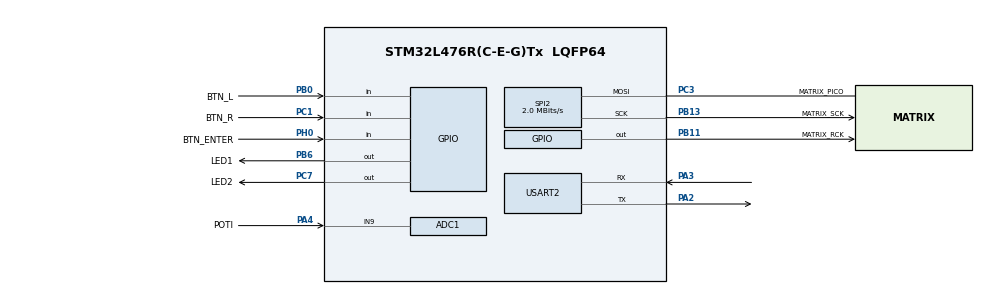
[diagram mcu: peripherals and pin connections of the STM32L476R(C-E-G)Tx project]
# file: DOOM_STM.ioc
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ADC1.Channel-0\#ChannelRegularConversion=ADC_CHANNEL_9
ADC1.ContinuousConvMode=ENABLE
ADC1.NbrOfConversionFlag=1
ADC1.OffsetNumber-0\#ChannelRegularConversion=ADC_OFFSET_NONE
ADC1.Rank-0\#ChannelRegularConversion=1
ADC1.SamplingTime-0\#ChannelRegularConversion=ADC_SAMPLETIME_2CYCLES_5
ADC1.master=1
Mcu.Family=STM32L4
Mcu.Name=STM32L476R(C-E-G)Tx
Mcu.Package=LQFP64
NVIC.PriorityGroup=NVIC_PRIORITYGROUP_4
PA2.Mode=Asynchronous
PA2.Signal=USART2_TX
PA3.Mode=Asynchronous
PA3.Signal=USART2_RX
PA4.GPIO_Label=POTI
PA4.Signal=ADCx_IN9
PB0.GPIO_Label=BTN_L
PB0.Signal=GPIO_Input
PB11.GPIO_Label=MATRIX_RCK
PB11.Signal=GPIO_Output
PB13.GPIO_Label=MATRIX_SCK
PB13.Mode=Simplex_Bidirectional_Master
PB13.Signal=SPI2_SCK
PB6.GPIO_Label=LED1
PB6.Signal=GPIO_Output
PC1.GPIO_Label=BTN_R
PC1.Signal=GPIO_Input
PC3.GPIO_Label=MATRIX_PICO
PC3.Mode=Simplex_Bidirectional_Master
PC3.Signal=SPI2_MOSI
PC7.GPIO_Label=LED2
PC7.Signal=GPIO_Output
PH0-OSC_IN\ (PH0).GPIO_Label=BTN_ENTER
PH0-OSC_IN\ (PH0).Signal=GPIO_Input
ProjectManager.HeapSize=0x200
ProjectManager.StackSize=0x400
ProjectManager.TargetToolchain=STM32CubeIDE
RCC.ADCFreq_Value=32000000
RCC.HSE_VALUE=8000000
RCC.HSI_VALUE=16000000
RCC.LSE_VALUE=32768
RCC.MSI_VALUE=4000000
RCC.PLLSAI1N=16
RCC.USBFreq_Value=32000000
RCC.VCOOutputFreq_Value=32000000
SH.ADCx_IN9.0=ADC1_IN9,IN9-Single-Ended
SPI2.CalculateBaudRate=2.0 MBits/s
SPI2.Direction=SPI_DIRECTION_1LINE
SPI2.Mode=SPI_MODE_MASTER
SPI2.VirtualType=VM_MASTER
USART2.VirtualMode-Asynchronous=VM_ASYNC
board=custom

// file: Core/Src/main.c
/* USER CODE BEGIN Header */
/**
 ******************************************************************************
 * @file           : main.c
 * @brief          : Main program body
 * @author         : Vikram Damani   (honestly so much of this is autogenerated that i dont think i should be credited alone up here)
 ******************************************************************************
 * @attention
 *
 * Copyright (c) 2023 STMicroelectronics.
 * All rights reserved.
 *
 * This software is licensed under terms that can be found in the LICENSE file
 * in the root directory of this software component.
 * If no LICENSE file comes with this software, it is provided AS-IS.
 *
 ******************************************************************************
 */
/* USER CODE END Header */
#include "main.h"

ADC_HandleTypeDef hadc1;

SPI_HandleTypeDef hspi2;

UART_HandleTypeDef huart2;

void SystemClock_Config(void);
static void MX_GPIO_Init(void);
static void MX_USART2_UART_Init(void);
static void MX_ADC1_Init(void);
static void MX_SPI2_Init(void);

int main(void)
{

  /* MCU Configuration--------------------------------------------------------*/

  /* Reset of all peripherals, Initializes the Flash interface and the Systick. */
  HAL_Init();

  /* Configure the system clock */
  SystemClock_Config();

  /* Initialize all configured peripherals */
  MX_GPIO_Init();
  MX_USART2_UART_Init();
  MX_ADC1_Init();
  MX_SPI2_Init();

  /* Infinite loop */
    while (1) {

    }
}

void SystemClock_Config(void)
{
  RCC_OscInitTypeDef RCC_OscInitStruct = {0};
  RCC_ClkInitTypeDef RCC_ClkInitStruct = {0};

  /** Configure the main internal regulator output voltage
  */
  if (HAL_PWREx_ControlVoltageScaling(PWR_REGULATOR_VOLTAGE_SCALE1) != HAL_OK)
  {
    Error_Handler();
  }

  /** Initializes the RCC Oscillators according to the specified parameters
  * in the RCC_OscInitTypeDef structure.
  */
  RCC_OscInitStruct.OscillatorType = RCC_OSCILLATORTYPE_MSI;
  RCC_OscInitStruct.MSIState = RCC_MSI_ON;
  RCC_OscInitStruct.MSICalibrationValue = 0;
  RCC_OscInitStruct.MSIClockRange = RCC_MSIRANGE_6;
  RCC_OscInitStruct.PLL.PLLState = RCC_PLL_NONE;
  if (HAL_RCC_OscConfig(&RCC_OscInitStruct) != HAL_OK)
  {
    Error_Handler();
  }

  /** Initializes the CPU, AHB and APB buses clocks
  */
  RCC_ClkInitStruct.ClockType = RCC_CLOCKTYPE_HCLK|RCC_CLOCKTYPE_SYSCLK
                              |RCC_CLOCKTYPE_PCLK1|RCC_CLOCKTYPE_PCLK2;
  RCC_ClkInitStruct.SYSCLKSource = RCC_SYSCLKSOURCE_MSI;
  RCC_ClkInitStruct.AHBCLKDivider = RCC_SYSCLK_DIV1;
  RCC_ClkInitStruct.APB1CLKDivider = RCC_HCLK_DIV1;
  RCC_ClkInitStruct.APB2CLKDivider = RCC_HCLK_DIV1;

  if (HAL_RCC_ClockConfig(&RCC_ClkInitStruct, FLASH_LATENCY_0) != HAL_OK)
  {
    Error_Handler();
  }
}

static void MX_ADC1_Init(void)
{

  ADC_MultiModeTypeDef multimode = {0};
  ADC_ChannelConfTypeDef sConfig = {0};

  /** Common config
  */
  hadc1.Instance = ADC1;
  hadc1.Init.ClockPrescaler = ADC_CLOCK_ASYNC_DIV1;
  hadc1.Init.Resolution = ADC_RESOLUTION_12B;
  hadc1.Init.DataAlign = ADC_DATAALIGN_RIGHT;
  hadc1.Init.ScanConvMode = ADC_SCAN_DISABLE;
  hadc1.Init.EOCSelection = ADC_EOC_SINGLE_CONV;
  hadc1.Init.LowPowerAutoWait = DISABLE;
  hadc1.Init.ContinuousConvMode = ENABLE;
  hadc1.Init.NbrOfConversion = 1;
  hadc1.Init.DiscontinuousConvMode = DISABLE;
  hadc1.Init.ExternalTrigConv = ADC_SOFTWARE_START;
  hadc1.Init.ExternalTrigConvEdge = ADC_EXTERNALTRIGCONVEDGE_NONE;
  hadc1.Init.DMAContinuousRequests = DISABLE;
  hadc1.Init.Overrun = ADC_OVR_DATA_PRESERVED;
  hadc1.Init.OversamplingMode = DISABLE;
  if (HAL_ADC_Init(&hadc1) != HAL_OK)
  {
    Error_Handler();
  }

  /** Configure the ADC multi-mode
  */
  multimode.Mode = ADC_MODE_INDEPENDENT;
  if (HAL_ADCEx_MultiModeConfigChannel(&hadc1, &multimode) != HAL_OK)
  {
    Error_Handler();
  }

  /** Configure Regular Channel
  */
  sConfig.Channel = ADC_CHANNEL_9;
  sConfig.Rank = ADC_REGULAR_RANK_1;
  sConfig.SamplingTime = ADC_SAMPLETIME_2CYCLES_5;
  sConfig.SingleDiff = ADC_SINGLE_ENDED;
  sConfig.OffsetNumber = ADC_OFFSET_NONE;
  sConfig.Offset = 0;
  if (HAL_ADC_ConfigChannel(&hadc1, &sConfig) != HAL_OK)
  {
    Error_Handler();
  }

}

static void MX_SPI2_Init(void)
{

  /* SPI2 parameter configuration*/
  hspi2.Instance = SPI2;
  hspi2.Init.Mode = SPI_MODE_MASTER;
  hspi2.Init.Direction = SPI_DIRECTION_1LINE;
  hspi2.Init.DataSize = SPI_DATASIZE_4BIT;
  hspi2.Init.CLKPolarity = SPI_POLARITY_LOW;
  hspi2.Init.CLKPhase = SPI_PHASE_1EDGE;
  hspi2.Init.NSS = SPI_NSS_SOFT;
  hspi2.Init.BaudRatePrescaler = SPI_BAUDRATEPRESCALER_2;
  hspi2.Init.FirstBit = SPI_FIRSTBIT_MSB;
  hspi2.Init.TIMode = SPI_TIMODE_DISABLE;
  hspi2.Init.CRCCalculation = SPI_CRCCALCULATION_DISABLE;
  hspi2.Init.CRCPolynomial = 7;
  hspi2.Init.CRCLength = SPI_CRC_LENGTH_DATASIZE;
  hspi2.Init.NSSPMode = SPI_NSS_PULSE_ENABLE;
  if (HAL_SPI_Init(&hspi2) != HAL_OK)
  {
    Error_Handler();
  }

}

static void MX_USART2_UART_Init(void)
{

  huart2.Instance = USART2;
  huart2.Init.BaudRate = 115200;
  huart2.Init.WordLength = UART_WORDLENGTH_8B;
  huart2.Init.StopBits = UART_STOPBITS_1;
  huart2.Init.Parity = UART_PARITY_NONE;
  huart2.Init.Mode = UART_MODE_TX_RX;
  huart2.Init.HwFlowCtl = UART_HWCONTROL_NONE;
  huart2.Init.OverSampling = UART_OVERSAMPLING_16;
  huart2.Init.OneBitSampling = UART_ONE_BIT_SAMPLE_DISABLE;
  huart2.AdvancedInit.AdvFeatureInit = UART_ADVFEATURE_NO_INIT;
  if (HAL_UART_Init(&huart2) != HAL_OK)
  {
    Error_Handler();
  }

}

static void MX_GPIO_Init(void)
{
  GPIO_InitTypeDef GPIO_InitStruct = {0};

  /* GPIO Ports Clock Enable */
  __HAL_RCC_GPIOH_CLK_ENABLE();
  __HAL_RCC_GPIOC_CLK_ENABLE();
  __HAL_RCC_GPIOA_CLK_ENABLE();
  __HAL_RCC_GPIOB_CLK_ENABLE();

  /*Configure GPIO pin Output Level */
  HAL_GPIO_WritePin(GPIOB, MATRIX_RCK_Pin|LED1_Pin, GPIO_PIN_RESET);

  /*Configure GPIO pin Output Level */
  HAL_GPIO_WritePin(LED2_GPIO_Port, LED2_Pin, GPIO_PIN_RESET);

  /*Configure GPIO pin : BTN_ENTER_Pin */
  GPIO_InitStruct.Pin = BTN_ENTER_Pin;
  GPIO_InitStruct.Mode = GPIO_MODE_INPUT;
  GPIO_InitStruct.Pull = GPIO_NOPULL;
  HAL_GPIO_Init(BTN_ENTER_GPIO_Port, &GPIO_InitStruct);

  /*Configure GPIO pin : BTN_R_Pin */
  GPIO_InitStruct.Pin = BTN_R_Pin;
  GPIO_InitStruct.Mode = GPIO_MODE_INPUT;
  GPIO_InitStruct.Pull = GPIO_NOPULL;
  HAL_GPIO_Init(BTN_R_GPIO_Port, &GPIO_InitStruct);

  /*Configure GPIO pin : BTN_L_Pin */
  GPIO_InitStruct.Pin = BTN_L_Pin;
  GPIO_InitStruct.Mode = GPIO_MODE_INPUT;
  GPIO_InitStruct.Pull = GPIO_NOPULL;
  HAL_GPIO_Init(BTN_L_GPIO_Port, &GPIO_InitStruct);

  /*Configure GPIO pins : MATRIX_RCK_Pin LED1_Pin */
  GPIO_InitStruct.Pin = MATRIX_RCK_Pin|LED1_Pin;
  GPIO_InitStruct.Mode = GPIO_MODE_OUTPUT_PP;
  GPIO_InitStruct.Pull = GPIO_NOPULL;
  GPIO_InitStruct.Speed = GPIO_SPEED_FREQ_LOW;
  HAL_GPIO_Init(GPIOB, &GPIO_InitStruct);

  /*Configure GPIO pin : LED2_Pin */
  GPIO_InitStruct.Pin = LED2_Pin;
  GPIO_InitStruct.Mode = GPIO_MODE_OUTPUT_PP;
  GPIO_InitStruct.Pull = GPIO_NOPULL;
  GPIO_InitStruct.Speed = GPIO_SPEED_FREQ_LOW;
  HAL_GPIO_Init(LED2_GPIO_Port, &GPIO_InitStruct);

}

/* USER CODE BEGIN 4 */
int _write(int file, char* ptr, int len)
{
    (void)file;

    HAL_UART_Transmit(&huart2, (uint8_t*)ptr, len, 10 * len);
    return len;
}

int __io_putchar(int ch)
{
    uint8_t buf = ch;
    HAL_UART_Transmit(&huart2, &buf, 1, 100);
    return 0;
}

int __io_getchar(void)
{
    uint8_t buf;
    HAL_UART_Receive(&huart2, &buf, 1, HAL_MAX_DELAY);
    return buf;
}
/* USER CODE END 4 */

void Error_Handler(void)
{
    __disable_irq();
    while (1) {
    }
}
